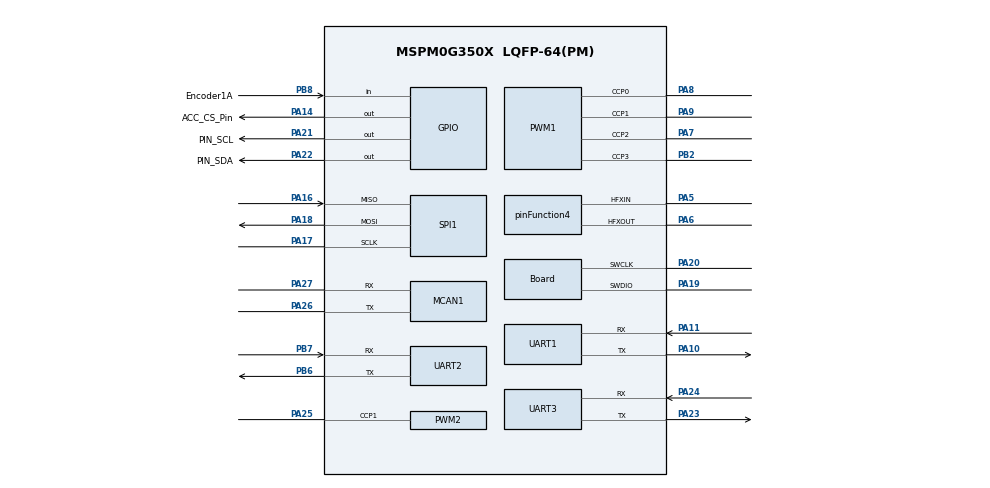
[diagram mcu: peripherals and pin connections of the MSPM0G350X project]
            /**
 * @cliArgs --device "MSPM0G350X" --part "Default" --package "LQFP-64(PM)" --product "mspm0_sdk@2.03.00.07"
 * @versions {"tool":"1.23.0+4000"}
 */

/**
 * Import the modules used in this configuration.
 */
const GPIO          = scripting.addModule("/ti/driverlib/GPIO", {}, false);
const GPIO1         = GPIO.addInstance();
const GPIO2         = GPIO.addInstance();
const GPIO3         = GPIO.addInstance();
const GPIO4         = GPIO.addInstance();
const GPIO5         = GPIO.addInstance();
const GPIO6         = GPIO.addInstance();
const MCAN          = scripting.addModule("/ti/driverlib/MCAN", {}, false);
const MCAN1         = MCAN.addInstance();
const PWM           = scripting.addModule("/ti/driverlib/PWM", {}, false); 
const PWM1          = PWM.addInstance();
const PWM2          = PWM.addInstance();
const SPI           = scripting.addModule("/ti/driverlib/SPI", {}, false);
const SPI1          = SPI.addInstance();
const SYSCTL        = scripting.addModule("/ti/driverlib/SYSCTL");
const SYSTICK       = scripting.addModule("/ti/driverlib/SYSTICK");
const TIMER         = scripting.addModule("/ti/driverlib/TIMER", {}, false);
const TIMER1        = TIMER.addInstance();
const TIMER2        = TIMER.addInstance();
const TIMER3        = TIMER.addInstance();
const TIMER4        = TIMER.addInstance();
const UART          = scripting.addModule("/ti/driverlib/UART", {}, false);
const UART1         = UART.addInstance();
const UART2         = UART.addInstance();
const UART3         = UART.addInstance();
const ProjectConfig = scripting.addModule("/ti/project_config/ProjectConfig");

/**
 * Write custom configuration values to the imported modules.
 */
const divider2       = system.clockTree["HFCLK4MFPCLKDIV"];
divider2.divideValue = 10;

const divider6       = system.clockTree["PLL_CLK2X_DIV"];
divider6.divideValue = 4;

const divider9       = system.clockTree["UDIV"];
divider9.divideValue = 2;

const gate7  = system.clockTree["MFCLKGATE"];
gate7.enable = true;

const gate8  = system.clockTree["MFPCLKGATE"];
gate8.enable = true;

const multiplier2         = system.clockTree["PLL_QDIV"];
multiplier2.multiplyValue = 4;

const mux2       = system.clockTree["CANCLKMUX"];
mux2.inputSelect = "CANCLKMUX_PLLCLK1_OUT";

const mux4       = system.clockTree["EXHFMUX"];
mux4.inputSelect = "EXHFMUX_XTAL";

const mux8       = system.clockTree["HSCLKMUX"];
mux8.inputSelect = "HSCLKMUX_SYSPLL0";

const mux9       = system.clockTree["LFXTMUX"];
mux9.inputSelect = "LFXTMUX_TRUE";

const mux10       = system.clockTree["MFPCLKMUX"];
mux10.inputSelect = "MFPCLKMUX_HFCLK";

const mux12       = system.clockTree["SYSPLLMUX"];
mux12.inputSelect = "zSYSPLLMUX_HFCLK";

const pinFunction4                        = system.clockTree["HFXT"];
pinFunction4.inputFreq                    = 40;
pinFunction4.enable                       = true;
pinFunction4.HFCLKMonitor                 = true;
pinFunction4.HFXTStartup                  = 20;
pinFunction4.peripheral.$assign           = "SYSCTL";
pinFunction4.peripheral.hfxInPin.$assign  = "PA5";
pinFunction4.peripheral.hfxOutPin.$assign = "PA6";

const pinFunction6              = system.clockTree["LFXT"];
pinFunction6.inputFreq          = 32.768;
pinFunction6.LFCLKMonitorEnable = true;

GPIO1.$name                              = "MotorDirection";
GPIO1.port                               = "PORTB";
GPIO1.associatedPins.create(4);
GPIO1.associatedPins[0].internalResistor = "PULL_DOWN";
GPIO1.associatedPins[0].$name            = "LeftFront";
GPIO1.associatedPins[0].assignedPin      = "9";
GPIO1.associatedPins[1].internalResistor = "PULL_DOWN";
GPIO1.associatedPins[1].$name            = "LeftRear";
GPIO1.associatedPins[1].assignedPin      = "16";
GPIO1.associatedPins[2].internalResistor = "PULL_DOWN";
GPIO1.associatedPins[2].$name            = "RightFront";
GPIO1.associatedPins[2].assignedPin      = "14";
GPIO1.associatedPins[3].internalResistor = "PULL_DOWN";
GPIO1.associatedPins[3].assignedPin      = "15";
GPIO1.associatedPins[3].$name            = "RightRear";

const Board                       = scripting.addModule("/ti/driverlib/Board", {}, false);
Board.peripheral.$assign          = "DEBUGSS";
Board.peripheral.swclkPin.$assign = "PA20";
Board.peripheral.swdioPin.$assign = "PA19";

GPIO2.port                           = "PORTA";
GPIO2.$name                          = "GPIO_OLED";
GPIO2.associatedPins.create(2);
GPIO2.associatedPins[0].initialValue = "SET";
GPIO2.associatedPins[0].$name        = "PIN_SCL";
GPIO2.associatedPins[0].assignedPin  = "21";
GPIO2.associatedPins[0].pin.$assign  = "PA21";
GPIO2.associatedPins[1].initialValue = "SET";
GPIO2.associatedPins[1].$name        = "PIN_SDA";
GPIO2.associatedPins[1].assignedPin  = "22";
GPIO2.associatedPins[1].pin.$assign  = "PA22";

GPIO3.$name                               = "Encoder1";
GPIO3.port                                = "PORTB";
GPIO3.associatedPins.create(2);
GPIO3.associatedPins[0].direction         = "INPUT";
GPIO3.associatedPins[0].internalResistor  = "PULL_DOWN";
GPIO3.associatedPins[0].interruptEn       = true;
GPIO3.associatedPins[0].polarity          = "RISE";
GPIO3.associatedPins[0].assignedPin       = "3";
GPIO3.associatedPins[0].$name             = "Encoder1B";
GPIO3.associatedPins[0].interruptPriority = "1";
GPIO3.associatedPins[1].direction         = "INPUT";
GPIO3.associatedPins[1].internalResistor  = "PULL_DOWN";
GPIO3.associatedPins[1].$name             = "Encoder1A";
GPIO3.associatedPins[1].assignedPin       = "8";
GPIO3.associatedPins[1].pin.$assign       = "PB8";

GPIO4.$name                               = "Encoder2";
GPIO4.port                                = "PORTA";
GPIO4.associatedPins.create(2);
GPIO4.associatedPins[0].direction         = "INPUT";
GPIO4.associatedPins[0].interruptEn       = true;
GPIO4.associatedPins[0].polarity          = "RISE";
GPIO4.associatedPins[0].assignedPin       = "13";
GPIO4.associatedPins[0].$name             = "Encoder2B";
GPIO4.associatedPins[0].interruptPriority = "1";
GPIO4.associatedPins[1].direction         = "INPUT";
GPIO4.associatedPins[1].assignedPin       = "12";
GPIO4.associatedPins[1].$name             = "Encoder2A";

GPIO5.$name                              = "GraySensor";
GPIO5.associatedPins.create(8);
GPIO5.associatedPins[0].$name            = "PIN_0";
GPIO5.associatedPins[0].direction        = "INPUT";
GPIO5.associatedPins[0].assignedPort     = "PORTB";
GPIO5.associatedPins[0].assignedPin      = "24";
GPIO5.associatedPins[0].internalResistor = "PULL_DOWN";
GPIO5.associatedPins[1].$name            = "PIN_1";
GPIO5.associatedPins[1].direction        = "INPUT";
GPIO5.associatedPins[1].assignedPort     = "PORTB";
GPIO5.associatedPins[1].assignedPin      = "20";
GPIO5.associatedPins[1].internalResistor = "PULL_DOWN";
GPIO5.associatedPins[2].$name            = "PIN_2";
GPIO5.associatedPins[2].assignedPort     = "PORTB";
GPIO5.associatedPins[2].assignedPin      = "19";
GPIO5.associatedPins[2].direction        = "INPUT";
GPIO5.associatedPins[2].internalResistor = "PULL_DOWN";
GPIO5.associatedPins[3].$name            = "PIN_3";
GPIO5.associatedPins[3].direction        = "INPUT";
GPIO5.associatedPins[3].assignedPort     = "PORTB";
GPIO5.associatedPins[3].assignedPin      = "18";
GPIO5.associatedPins[3].internalResistor = "PULL_DOWN";
GPIO5.associatedPins[4].$name            = "PIN_4";
GPIO5.associatedPins[4].direction        = "INPUT";
GPIO5.associatedPins[4].assignedPort     = "PORTA";
GPIO5.associatedPins[4].assignedPin      = "0";
GPIO5.associatedPins[5].$name            = "PIN_5";
GPIO5.associatedPins[5].direction        = "INPUT";
GPIO5.associatedPins[5].assignedPort     = "PORTA";
GPIO5.associatedPins[5].assignedPin      = "1";
GPIO5.associatedPins[6].$name            = "PIN_6";
GPIO5.associatedPins[6].direction        = "INPUT";
GPIO5.associatedPins[6].assignedPort     = "PORTA";
GPIO5.associatedPins[6].assignedPin      = "28";
GPIO5.associatedPins[7].$name            = "PIN_7";
GPIO5.associatedPins[7].direction        = "INPUT";
GPIO5.associatedPins[7].assignedPort     = "PORTA";
GPIO5.associatedPins[7].assignedPin      = "31";

GPIO6.$name                         = "CS";
GPIO6.port                          = "PORTA";
GPIO6.associatedPins.create(2);
GPIO6.associatedPins[0].$name       = "ACC_CS_Pin";
GPIO6.associatedPins[0].assignedPin = "14";
GPIO6.associatedPins[0].pin.$assign = "PA14";
GPIO6.associatedPins[1].$name       = "GYRO_CS_Pin";
GPIO6.associatedPins[1].assignedPin = "15";

MCAN1.$name                    = "MCAN0";
MCAN1.brsEnable                = false;
MCAN1.peripheral.$assign       = "CANFD0";
MCAN1.peripheral.rxPin.$assign = "PA27";
MCAN1.peripheral.txPin.$assign = "PA26";
MCAN1.txPinConfig.$name        = "ti_driverlib_gpio_GPIOPinGeneric6";
MCAN1.rxPinConfig.$name        = "ti_driverlib_gpio_GPIOPinGeneric7";

PWM1.clockDivider                       = 8;
PWM1.ccIndex                            = [0,1,2,3];
PWM1.$name                              = "PWM_Motors";
PWM1.timerCount                         = 1001;
PWM1.PWM_CHANNEL_0.$name                = "ti_driverlib_pwm_PWMTimerCC0";
PWM1.PWM_CHANNEL_1.$name                = "ti_driverlib_pwm_PWMTimerCC1";
PWM1.ccp0PinConfig.direction            = scripting.forceWrite("OUTPUT");
PWM1.ccp0PinConfig.hideOutputInversion  = scripting.forceWrite(false);
PWM1.ccp0PinConfig.onlyInternalResistor = scripting.forceWrite(false);
PWM1.ccp0PinConfig.passedPeripheralType = scripting.forceWrite("Digital");
PWM1.ccp0PinConfig.$name                = "ti_driverlib_gpio_GPIOPinGeneric10";
PWM1.ccp1PinConfig.direction            = scripting.forceWrite("OUTPUT");
PWM1.ccp1PinConfig.hideOutputInversion  = scripting.forceWrite(false);
PWM1.ccp1PinConfig.onlyInternalResistor = scripting.forceWrite(false);
PWM1.ccp1PinConfig.passedPeripheralType = scripting.forceWrite("Digital");
PWM1.ccp1PinConfig.$name                = "ti_driverlib_gpio_GPIOPinGeneric11";
PWM1.peripheral.$assign                 = "TIMA0";
PWM1.peripheral.ccp0Pin.$assign         = "PA8";
PWM1.peripheral.ccp1Pin.$assign         = "PA9";
PWM1.peripheral.ccp2Pin.$assign         = "PA7";
PWM1.peripheral.ccp3Pin.$assign         = "PB2";
PWM1.PWM_CHANNEL_2.$name                = "ti_driverlib_pwm_PWMTimerCC2";
PWM1.PWM_CHANNEL_3.$name                = "ti_driverlib_pwm_PWMTimerCC3";
PWM1.ccp2PinConfig.direction            = scripting.forceWrite("OUTPUT");
PWM1.ccp2PinConfig.hideOutputInversion  = scripting.forceWrite(false);
PWM1.ccp2PinConfig.onlyInternalResistor = scripting.forceWrite(false);
PWM1.ccp2PinConfig.passedPeripheralType = scripting.forceWrite("Digital");
PWM1.ccp2PinConfig.$name                = "ti_driverlib_gpio_GPIOPinGeneric12";
PWM1.ccp3PinConfig.direction            = scripting.forceWrite("OUTPUT");
PWM1.ccp3PinConfig.hideOutputInversion  = scripting.forceWrite(false);
PWM1.ccp3PinConfig.onlyInternalResistor = scripting.forceWrite(false);
PWM1.ccp3PinConfig.passedPeripheralType = scripting.forceWrite("Digital");
PWM1.ccp3PinConfig.$name                = "ti_driverlib_gpio_GPIOPinGeneric13";

PWM2.$name                              = "PWM_Buzzer";
PWM2.ccIndex                            = [1];
PWM2.clockDivider                       = 8;
PWM2.ccp1PinConfig.direction            = scripting.forceWrite("OUTPUT");
PWM2.ccp1PinConfig.hideOutputInversion  = scripting.forceWrite(false);
PWM2.ccp1PinConfig.onlyInternalResistor = scripting.forceWrite(false);
PWM2.ccp1PinConfig.passedPeripheralType = scripting.forceWrite("Digital");
PWM2.ccp1PinConfig.$name                = "ti_driverlib_gpio_GPIOPinGeneric8";
PWM2.peripheral.$assign                 = "TIMG12";
PWM2.peripheral.ccp1Pin.$assign         = "PA25";
PWM2.PWM_CHANNEL_1.$name                = "ti_driverlib_pwm_PWMTimerCC4";

SPI1.$name                              = "SPI_Bmi088";
SPI1.targetBitRate                      = 10000000;
SPI1.chipSelect                         = [];
SPI1.frameFormat                        = "MOTO3";
SPI1.sclkPinConfig.direction            = scripting.forceWrite("OUTPUT");
SPI1.sclkPinConfig.onlyInternalResistor = scripting.forceWrite(false);
SPI1.sclkPinConfig.passedPeripheralType = scripting.forceWrite("Digital");
SPI1.sclkPinConfig.$name                = "ti_driverlib_gpio_GPIOPinGeneric9";
SPI1.mosiPinConfig.direction            = scripting.forceWrite("OUTPUT");
SPI1.mosiPinConfig.hideOutputInversion  = scripting.forceWrite(false);
SPI1.mosiPinConfig.onlyInternalResistor = scripting.forceWrite(false);
SPI1.mosiPinConfig.passedPeripheralType = scripting.forceWrite("Digital");
SPI1.mosiPinConfig.$name                = "ti_driverlib_gpio_GPIOPinGeneric14";
SPI1.misoPinConfig.onlyInternalResistor = scripting.forceWrite(false);
SPI1.misoPinConfig.passedPeripheralType = scripting.forceWrite("Digital");
SPI1.misoPinConfig.$name                = "ti_driverlib_gpio_GPIOPinGeneric15";
SPI1.peripheral.$assign                 = "SPI1";
SPI1.peripheral.sclkPin.$assign         = "PA17";
SPI1.peripheral.mosiPin.$assign         = "PA18";
SPI1.peripheral.misoPin.$assign         = "PA16";

SYSCTL.validateClkStatus     = true;
SYSCTL.HFCLKSource           = "HFXT";
SYSCTL.waitState             = "1";
SYSCTL.enableSYSOSCFCL       = true;
SYSCTL.enableROSC            = true;
SYSCTL.forceDefaultClkConfig = true;
SYSCTL.clockTreeEn           = true;

SYSTICK.periodEnable      = true;
SYSTICK.period            = 80000;
SYSTICK.interruptEnable   = true;
SYSTICK.systickEnable     = true;
SYSTICK.interruptPriority = "0";

TIMER1.timerClkDiv        = 8;
TIMER1.timerClkPrescale   = 100;
TIMER1.timerMode          = "PERIODIC";
TIMER1.interrupts         = ["ZERO"];
TIMER1.timerPeriod        = "100 ms";
TIMER1.$name              = "TIMERA1_10hz";
TIMER1.peripheral.$assign = "TIMA1";

TIMER2.timerClkDiv        = 8;
TIMER2.timerClkPrescale   = 100;
TIMER2.timerMode          = "PERIODIC";
TIMER2.timerPeriod        = "5 ms";
TIMER2.interrupts         = ["ZERO"];
TIMER2.$name              = "TIMERG7_200hz";
TIMER2.peripheral.$assign = "TIMG7";

TIMER3.$name              = "TIMERG8_100hz";
TIMER3.timerClkDiv        = 8;
TIMER3.timerClkPrescale   = 100;
TIMER3.timerMode          = "PERIODIC";
TIMER3.timerPeriod        = "10 ms";
TIMER3.interrupts         = ["ZERO"];
TIMER3.peripheral.$assign = "TIMG8";

TIMER4.timerClkDiv        = 8;
TIMER4.timerMode          = "PERIODIC";
TIMER4.interrupts         = ["ZERO"];
TIMER4.timerPeriod        = "1 ms";
TIMER4.$name              = "TIMERG6_1000hz";
TIMER4.peripheral.$assign = "TIMG6";

UART1.$name                    = "UART_0";
UART1.targetBaudRate           = 115200;
UART1.rxFifoThreshold          = "DL_UART_RX_FIFO_LEVEL_ONE_ENTRY";
UART1.enableDMARX              = false;
UART1.enableDMATX              = false;
UART1.enabledInterrupts        = ["RX"];
UART1.interruptPriority        = "1";
UART1.peripheral.$assign       = "UART0";
UART1.peripheral.rxPin.$assign = "PA11";
UART1.peripheral.txPin.$assign = "PA10";
UART1.txPinConfig.$name        = "ti_driverlib_gpio_GPIOPinGeneric0";
UART1.rxPinConfig.$name        = "ti_driverlib_gpio_GPIOPinGeneric1";

UART2.$name                    = "UART_1";
UART2.enabledInterrupts        = ["RX"];
UART2.interruptPriority        = "0";
UART2.targetBaudRate           = 256000;
UART2.peripheral.$assign       = "UART1";
UART2.peripheral.rxPin.$assign = "PB7";
UART2.peripheral.txPin.$assign = "PB6";
UART2.txPinConfig.$name        = "ti_driverlib_gpio_GPIOPinGeneric2";
UART2.rxPinConfig.$name        = "ti_driverlib_gpio_GPIOPinGeneric3";

UART3.$name                    = "UART_2";
UART3.uartClkSrc               = "MFCLK";
UART3.peripheral.$assign       = "UART2";
UART3.peripheral.rxPin.$assign = "PA24";
UART3.peripheral.txPin.$assign = "PA23";
UART3.txPinConfig.$name        = "ti_driverlib_gpio_GPIOPinGeneric4";
UART3.rxPinConfig.$name        = "ti_driverlib_gpio_GPIOPinGeneric5";

ProjectConfig.deviceSpin  = "MSPM0G3507";
ProjectConfig.genLibCMSIS = true;

/**
 * Pinmux solution for unlocked pins/peripherals. This ensures that minor changes to the automatic solver in a future
 * version of the tool will not impact the pinmux you originally saw.  These lines can be completely deleted in order to
 * re-solve from scratch.
 */
GPIO1.associatedPins[0].pin.$suggestSolution = "PB9";
GPIO1.associatedPins[1].pin.$suggestSolution = "PB16";
GPIO1.associatedPins[2].pin.$suggestSolution = "PB14";
GPIO1.associatedPins[3].pin.$suggestSolution = "PB15";
GPIO3.associatedPins[0].pin.$suggestSolution = "PB3";
GPIO4.associatedPins[0].pin.$suggestSolution = "PA13";
GPIO4.associatedPins[1].pin.$suggestSolution = "PA12";
GPIO5.associatedPins[0].pin.$suggestSolution = "PB24";
GPIO5.associatedPins[1].pin.$suggestSolution = "PB20";
GPIO5.associatedPins[2].pin.$suggestSolution = "PB19";
GPIO5.associatedPins[3].pin.$suggestSolution = "PB18";
GPIO5.associatedPins[4].pin.$suggestSolution = "PA0";
GPIO5.associatedPins[5].pin.$suggestSolution = "PA1";
GPIO5.associatedPins[6].pin.$suggestSolution = "PA28";
GPIO5.associatedPins[7].pin.$suggestSolution = "PA31";
GPIO6.associatedPins[1].pin.$suggestSolution = "PA15";
